AUTOSAR XML (schema 4-2-2)
package /ComponentTypes
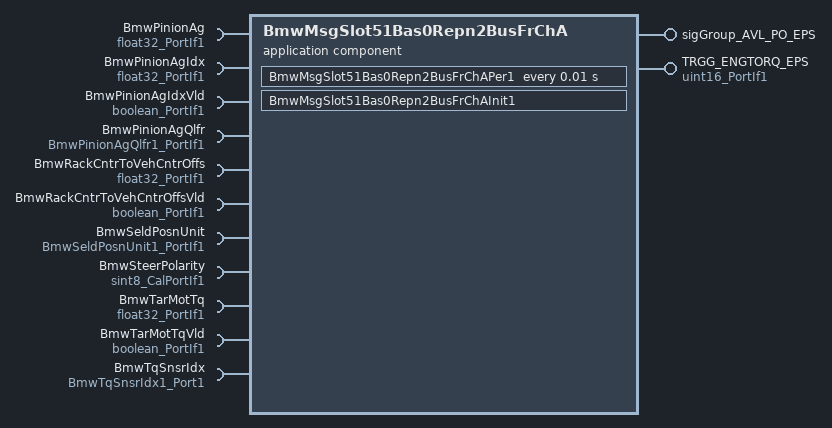
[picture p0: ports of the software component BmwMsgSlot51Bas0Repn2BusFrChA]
  application sw component type BmwMsgSlot51Bas0Repn2BusFrChA
    provide port sigGroup_AVL_PO_EPS: nonqueued-sender-com-spec{data-element=sigGroup_AVL_PO_EPS, uses-end-to-end-protection=true, init-value=fields=[AVL_PO_EPS:65535, IDX_TORQ_SEN:3, OFFS_GRD_MID_EPS:4095, AVL_PO_IDX_EPS:65535, CRC_AVL_PO_EPS:0, QU_AVL_PO_EPS:15, ALIV_AVL_PO_EPS:15, UN_PO_EPS:0]}, provided-interface=sigGroup_AVL_PO_EPS
    provide port TRGG_ENGTORQ_EPS: nonqueued-sender-com-spec{data-element=Val, init-value=4095}, provided-interface=uint16_PortIf1
    11 x require port:
      BmwPinionAg: nonqueued-receiver-com-spec{data-element=Val, filter=data-filter-type=ALWAYS, init-value=0}, required-interface=float32_PortIf1
      BmwPinionAgIdx: nonqueued-receiver-com-spec{data-element=Val, filter=data-filter-type=ALWAYS, init-value=0}, required-interface=float32_PortIf1
      BmwPinionAgIdxVld: nonqueued-receiver-com-spec{data-element=Logl, filter=data-filter-type=ALWAYS, init-value=0}, required-interface=boolean_PortIf1
      BmwPinionAgQlfr: nonqueued-receiver-com-spec{data-element=Val, filter=data-filter-type=ALWAYS, init-value=14}, required-interface=BmwPinionAgQlfr1_PortIf1
      BmwRackCntrToVehCntrOffs: nonqueued-receiver-com-spec{data-element=Val, filter=data-filter-type=ALWAYS, init-value=0}, required-interface=float32_PortIf1
      BmwRackCntrToVehCntrOffsVld: nonqueued-receiver-com-spec{data-element=Logl, filter=data-filter-type=ALWAYS, init-value=0}, required-interface=boolean_PortIf1
      BmwSeldPosnUnit: nonqueued-receiver-com-spec{data-element=Val, filter=data-filter-type=ALWAYS, init-value=0}, required-interface=BmwSeldPosnUnit1_PortIf1
      BmwSteerPolarity: parameter-require-com-spec{init-value=-1, parameter=Val}, required-interface=sint8_CalPortIf1
      BmwTarMotTq: nonqueued-receiver-com-spec{data-element=Val, filter=data-filter-type=ALWAYS, init-value=0}, required-interface=float32_PortIf1
      BmwTarMotTqVld: nonqueued-receiver-com-spec{data-element=Logl, filter=data-filter-type=ALWAYS, init-value=0}, required-interface=boolean_PortIf1
      BmwTqSnsrIdx: nonqueued-receiver-com-spec{data-element=Val, filter=data-filter-type=ALWAYS, init-value=3}, required-interface=BmwTqSnsrIdx1_Port1
    behavior BmwMsgSlot51Bas0Repn2BusFrChA_InternalBehavior
      init event BmwMsgSlot51Bas0Repn2BusFrChA_InitEvent: start-on-event=BmwMsgSlot51Bas0Repn2BusFrChAInit1
      timing event TMT_BmwMsgSlot51Bas0Repn2BusFrChAPer1: start-on-event=BmwMsgSlot51Bas0Repn2BusFrChAPer1, period=0.01
      port-api-options:
        enable-take-address=false, error-handling=NO-TRANSFORMER-ERROR-HANDLING, indirect-api=false, port=BmwPinionAg
        enable-take-address=false, error-handling=NO-TRANSFORMER-ERROR-HANDLING, indirect-api=false, port=BmwPinionAgIdx
        enable-take-address=false, error-handling=NO-TRANSFORMER-ERROR-HANDLING, indirect-api=false, port=BmwPinionAgIdxVld
        enable-take-address=false, error-handling=NO-TRANSFORMER-ERROR-HANDLING, indirect-api=false, port=BmwPinionAgQlfr
        enable-take-address=false, error-handling=NO-TRANSFORMER-ERROR-HANDLING, indirect-api=false, port=BmwRackCntrToVehCntrOffs
        enable-take-address=false, error-handling=NO-TRANSFORMER-ERROR-HANDLING, indirect-api=false, port=BmwRackCntrToVehCntrOffsVld
        enable-take-address=false, error-handling=NO-TRANSFORMER-ERROR-HANDLING, indirect-api=false, port=BmwSeldPosnUnit
        enable-take-address=false, error-handling=NO-TRANSFORMER-ERROR-HANDLING, indirect-api=false, port=BmwSteerPolarity
        enable-take-address=false, error-handling=NO-TRANSFORMER-ERROR-HANDLING, indirect-api=false, port=BmwTarMotTq
        enable-take-address=false, error-handling=NO-TRANSFORMER-ERROR-HANDLING, indirect-api=false, port=BmwTarMotTqVld
        enable-take-address=false, error-handling=NO-TRANSFORMER-ERROR-HANDLING, indirect-api=false, port=BmwTqSnsrIdx
        enable-take-address=false, error-handling=NO-TRANSFORMER-ERROR-HANDLING, indirect-api=false, port=sigGroup_AVL_PO_EPS
        enable-take-address=false, error-handling=NO-TRANSFORMER-ERROR-HANDLING, indirect-api=false, port=TRGG_ENGTORQ_EPS
      runnable BmwMsgSlot51Bas0Repn2BusFrChAInit1
      runnable BmwMsgSlot51Bas0Repn2BusFrChAPer1
        data-receive-point-by-arguments:
          10 x access:
            REC_BmwPinionAg_Val: accessed-variable=BmwPinionAg.Val
            REC_BmwPinionAgIdx_Val: accessed-variable=BmwPinionAgIdx.Val
            REC_BmwPinionAgIdxVld_Logl: accessed-variable=BmwPinionAgIdxVld.Logl
            REC_BmwPinionAgQlfr_Val: accessed-variable=BmwPinionAgQlfr.Val
            REC_BmwRackCntrToVehCntrOffs_Val: accessed-variable=BmwRackCntrToVehCntrOffs.Val
            REC_BmwRackCntrToVehCntrOffsVld_Logl: accessed-variable=BmwRackCntrToVehCntrOffsVld.Logl
            REC_BmwSeldPosnUnit_Val: accessed-variable=BmwSeldPosnUnit.Val
            REC_BmwTarMotTq_Val_1: accessed-variable=BmwTarMotTq.Val
            REC_BmwTarMotTqVld_Logl_1: accessed-variable=BmwTarMotTqVld.Logl
            REC_BmwTqSnsrIdx_Val: accessed-variable=BmwTqSnsrIdx.Val
        data-send-points:
          access SEND_sigGroup_AVL_PO_EPS_sigGroup_AVL_PO_EPS: accessed-variable=sigGroup_AVL_PO_EPS.sigGroup_AVL_PO_EPS
          access SEND_TRGG_ENGTORQ_EPS_Val: accessed-variable=TRGG_ENGTORQ_EPS.Val
  swc implementation BmwMsgSlot51Bas0Repn2BusFrChA_Implementation: behavior=BmwMsgSlot51Bas0Repn2BusFrChA_InternalBehavior
    code-descriptors:
      code Default: artifact-descriptors=autosar-engineering-object={short-label=Default, category=SWSRC}
